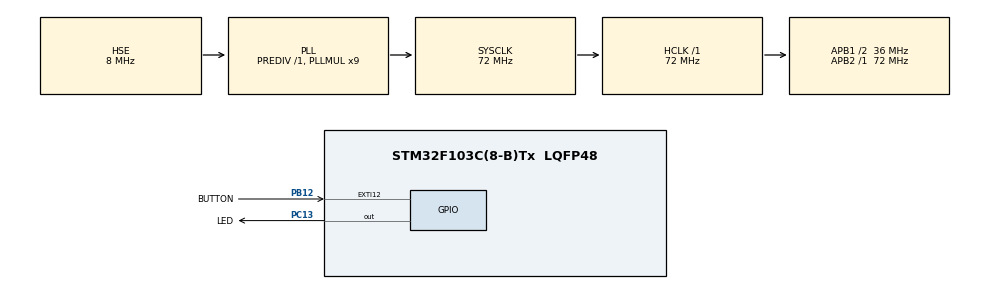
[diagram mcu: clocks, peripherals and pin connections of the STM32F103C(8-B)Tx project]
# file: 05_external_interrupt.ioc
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Mcu.Family=STM32F1
RCC.PLLSourceVirtual=RCC_PLLSOURCE_HSE
PD1-OSC_OUT.Mode=HSE-External-Oscillator
PC13-TAMPER-RTC.Signal=GPIO_Output
PD0-OSC_IN.Signal=RCC_OSC_IN
RCC.APB1CLKDivider=RCC_HCLK_DIV2
RCC.SYSCLKSource=RCC_SYSCLKSOURCE_PLLCLK
ProjectManager.StackSize=0x400
PD1-OSC_OUT.Signal=RCC_OSC_OUT
PA13.Signal=SYS_JTMS-SWDIO
ProjectManager.TargetToolchain=STM32CubeIDE
RCC.HCLKFreq_Value=72000000
RCC.APB2TimFreq_Value=72000000
RCC.USBFreq_Value=72000000
RCC.AHBFreq_Value=72000000
PD0-OSC_IN.Mode=HSE-External-Oscillator
NVIC.EXTI15_10_IRQn=true\:15\:0\:true\:false\:true\:true\:true
board=custom
RCC.PLLMUL=RCC_PLL_MUL9
PC13-TAMPER-RTC.GPIO_Label=LED
PB12.GPIO_Label=BUTTON
RCC.APB2Freq_Value=72000000
PA14.Mode=Serial_Wire
PA13.Mode=Serial_Wire
Mcu.Name=STM32F103C(8-B)Tx
RCC.SYSCLKFreq_VALUE=72000000
Mcu.Package=LQFP48
PA14.Signal=SYS_JTCK-SWCLK
ProjectManager.HeapSize=0x200
NVIC.PriorityGroup=NVIC_PRIORITYGROUP_4
RCC.APB1TimFreq_Value=72000000
PB12.GPIO_PuPd=GPIO_PULLDOWN
RCC.APB1Freq_Value=36000000
PB12.Signal=GPXTI12

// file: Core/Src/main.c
/* USER CODE BEGIN Header */
/**
  ******************************************************************************
  * @file           : main.c
  * @brief          : Main program body
  ******************************************************************************
  * @attention
  *
  * <h2><center>&copy; Copyright (c) 2021 STMicroelectronics.
  * All rights reserved.</center></h2>
  *
  * This software component is licensed by ST under BSD 3-Clause license,
  * the "License"; You may not use this file except in compliance with the
  * License. You may obtain a copy of the License at:
  *                        opensource.org/licenses/BSD-3-Clause
  *
  ******************************************************************************
  */
/* USER CODE END Header */
#include "main.h"

/* USER CODE BEGIN PV */
uint16_t sayi=0;
/* USER CODE END PV */

void SystemClock_Config(void);
static void MX_GPIO_Init(void);

int main(void)
{

  /* MCU Configuration--------------------------------------------------------*/

  /* Reset of all peripherals, Initializes the Flash interface and the Systick. */
  HAL_Init();

  /* Configure the system clock */
  SystemClock_Config();

  /* Initialize all configured peripherals */
  MX_GPIO_Init();
  /* USER CODE BEGIN 2 */
  HAL_GPIO_WritePin(LED_GPIO_Port,LED_Pin,GPIO_PIN_SET);
  /* USER CODE END 2 */

  /* Infinite loop */
  while (1)
  {

  }
}

void SystemClock_Config(void)
{
  RCC_OscInitTypeDef RCC_OscInitStruct = {0};
  RCC_ClkInitTypeDef RCC_ClkInitStruct = {0};

  /** Initializes the RCC Oscillators according to the specified parameters
  * in the RCC_OscInitTypeDef structure.
  */
  RCC_OscInitStruct.OscillatorType = RCC_OSCILLATORTYPE_HSE;
  RCC_OscInitStruct.HSEState = RCC_HSE_ON;
  RCC_OscInitStruct.HSEPredivValue = RCC_HSE_PREDIV_DIV1;
  RCC_OscInitStruct.HSIState = RCC_HSI_ON;
  RCC_OscInitStruct.PLL.PLLState = RCC_PLL_ON;
  RCC_OscInitStruct.PLL.PLLSource = RCC_PLLSOURCE_HSE;
  RCC_OscInitStruct.PLL.PLLMUL = RCC_PLL_MUL9;
  if (HAL_RCC_OscConfig(&RCC_OscInitStruct) != HAL_OK)
  {
    Error_Handler();
  }
  /** Initializes the CPU, AHB and APB buses clocks
  */
  RCC_ClkInitStruct.ClockType = RCC_CLOCKTYPE_HCLK|RCC_CLOCKTYPE_SYSCLK
                              |RCC_CLOCKTYPE_PCLK1|RCC_CLOCKTYPE_PCLK2;
  RCC_ClkInitStruct.SYSCLKSource = RCC_SYSCLKSOURCE_PLLCLK;
  RCC_ClkInitStruct.AHBCLKDivider = RCC_SYSCLK_DIV1;
  RCC_ClkInitStruct.APB1CLKDivider = RCC_HCLK_DIV2;
  RCC_ClkInitStruct.APB2CLKDivider = RCC_HCLK_DIV1;

  if (HAL_RCC_ClockConfig(&RCC_ClkInitStruct, FLASH_LATENCY_2) != HAL_OK)
  {
    Error_Handler();
  }
}

static void MX_GPIO_Init(void)
{
  GPIO_InitTypeDef GPIO_InitStruct = {0};

  /* GPIO Ports Clock Enable */
  __HAL_RCC_GPIOC_CLK_ENABLE();
  __HAL_RCC_GPIOD_CLK_ENABLE();
  __HAL_RCC_GPIOB_CLK_ENABLE();
  __HAL_RCC_GPIOA_CLK_ENABLE();

  /*Configure GPIO pin Output Level */
  HAL_GPIO_WritePin(LED_GPIO_Port, LED_Pin, GPIO_PIN_RESET);

  /*Configure GPIO pin : LED_Pin */
  GPIO_InitStruct.Pin = LED_Pin;
  GPIO_InitStruct.Mode = GPIO_MODE_OUTPUT_PP;
  GPIO_InitStruct.Pull = GPIO_NOPULL;
  GPIO_InitStruct.Speed = GPIO_SPEED_FREQ_LOW;
  HAL_GPIO_Init(LED_GPIO_Port, &GPIO_InitStruct);

  /*Configure GPIO pin : BUTTON_Pin */
  GPIO_InitStruct.Pin = BUTTON_Pin;
  GPIO_InitStruct.Mode = GPIO_MODE_IT_RISING;
  GPIO_InitStruct.Pull = GPIO_PULLDOWN;
  HAL_GPIO_Init(BUTTON_GPIO_Port, &GPIO_InitStruct);

  /* EXTI interrupt init*/
  HAL_NVIC_SetPriority(EXTI15_10_IRQn, 15, 0);
  HAL_NVIC_EnableIRQ(EXTI15_10_IRQn);

}

/* USER CODE BEGIN 4 */
void HAL_GPIO_EXTI_Callback(uint16_t GPIO_Pin)
{
	HAL_GPIO_TogglePin(LED_GPIO_Port,LED_Pin);
	sayi++;
}

/* USER CODE END 4 */

void Error_Handler(void)
{
  __disable_irq();
  while (1)
  {
  }
}

/************************ (C) COPYRIGHT STMicroelectronics *****END OF FILE****/
